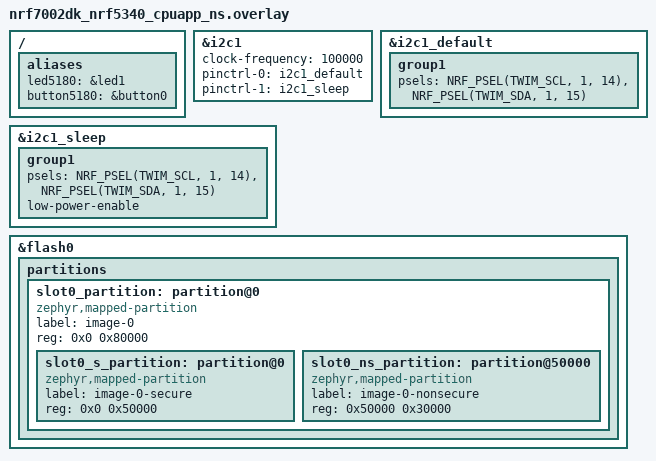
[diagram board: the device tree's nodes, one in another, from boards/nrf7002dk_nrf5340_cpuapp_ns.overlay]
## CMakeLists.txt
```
cmake_minimum_required(VERSION 3.20.0)

find_package(Zephyr REQUIRED HINTS $ENV{ZEPHYR_BASE})
project(blinky)

target_sources(app PRIVATE src/main.c)
target_sources_ifdef(CONFIG_LAB_BME280 app PRIVATE bme280/bme280_raw.c bme280/bme280_app.c)

if(CONFIG_SUM_PRINT)
	target_sources(app PRIVATE sum_printk/sum_printk.c)
	target_include_directories(app PRIVATE sum_printk)
elseif(CONFIG_SUM_LOG)
	target_sources(app PRIVATE sum_log/sum_log.c)
	target_include_directories(app PRIVATE sum_log)
endif()
```

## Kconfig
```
mainmenu "Sum Application Configuration"

choice SUM_IMPLEMENTATION
	prompt "Select the sum output implementation"
	default SUM_PRINT

config SUM_PRINT
	bool "Use printk implementation"
	select PRINTK

config SUM_LOG
	bool "Use Logger implementation"
	select LOG

endchoice

config LAB_BME280
	bool "Part 8 BME280 register temperature reader"
	depends on I2C

source "Kconfig.zephyr"
```

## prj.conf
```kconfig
CONFIG_GPIO=y
CONFIG_CONSOLE=y
CONFIG_SERIAL=y
CONFIG_UART_CONSOLE=y

CONFIG_LOG=y
CONFIG_LOG_DEFAULT_LEVEL=3
CONFIG_SUM_LOG=y

CONFIG_I2C=y
CONFIG_SENSOR=y
CONFIG_LAB_BME280=y
# UART1 and I2C1 share a hardware instance; reserve it for I2C1.
CONFIG_TFM_SECURE_UART=n
CONFIG_TFM_LOG_LEVEL_SILENCE=y
```

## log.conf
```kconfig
# Apply after prj.conf with -DEXTRA_CONF_FILE=log.conf.
CONFIG_SUM_PRINT=n
CONFIG_SUM_LOG=y
CONFIG_LOG=y
CONFIG_LOG_DEFAULT_LEVEL=3
CONFIG_LOG_MODE_DEFERRED=y
CONFIG_LOG_BACKEND_UART=y
```

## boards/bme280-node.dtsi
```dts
bme280_lab: bme280@77 {
 compatible = "i2c-device";
 reg = <0x77>;
 status = "okay";
};
```

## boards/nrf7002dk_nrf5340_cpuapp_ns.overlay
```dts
/ {
	aliases {
		led5180 = &led1;
		button5180 = &button0;
	};
};

&i2c1 {
	status = "okay";
	clock-frequency = <100000>;
	pinctrl-0 = <&i2c1_default>;
	pinctrl-1 = <&i2c1_sleep>;
	pinctrl-names = "default", "sleep";
	#include "bme280-node.dtsi"
};

&i2c1_default {
	group1 {
		psels = <NRF_PSEL(TWIM_SCL, 1, 14)>, <NRF_PSEL(TWIM_SDA, 1, 15)>;
	};
};

&i2c1_sleep {
	group1 {
		psels = <NRF_PSEL(TWIM_SCL, 1, 14)>, <NRF_PSEL(TWIM_SDA, 1, 15)>;
		low-power-enable;
	};
};

/* This application boots TF-M directly, without MCUboot. */
/delete-node/ &boot_partition;
/delete-node/ &slot0_partition;

&flash0 {
	partitions {
		slot0_partition: partition@0 {
			compatible = "zephyr,mapped-partition";
			label = "image-0";
			reg = <0x0 0x80000>;
			ranges = <0x0 0x0 0x80000>;
			#address-cells = <1>;
			#size-cells = <1>;

			slot0_s_partition: partition@0 {
				compatible = "zephyr,mapped-partition";
				label = "image-0-secure";
				reg = <0x0 0x50000>;
			};

			slot0_ns_partition: partition@50000 {
				compatible = "zephyr,mapped-partition";
				label = "image-0-nonsecure";
				reg = <0x50000 0x30000>;
			};
		};
	};
};
```

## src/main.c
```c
/*
 * Copyright (c) 2016 Intel Corporation
 *
 * SPDX-License-Identifier: Apache-2.0
 */

#include <stdio.h>
#include <zephyr/kernel.h>
#include <zephyr/drivers/gpio.h>

#ifdef CONFIG_SUM_PRINT
#include "sum_printk.h"
#elif defined(CONFIG_SUM_LOG)
#include "sum_log.h"
#endif

/* 1000 msec = 1 sec */
#define SLEEP_TIME_MS   2000
#define BUTTON_POLL_TIME_MS 20

/* The devicetree node identifier for the "led0" alias. */
//#define LED0_NODE DT_ALIAS(led0)
//#define BUTTON_NODE DT_ALIAS(sw0)
#define LED5180_NODE DT_ALIAS(led5180)
#define BUTTON5180_NODE DT_ALIAS(button5180)

/*
 * A build error on this line means your board is unsupported.
 * See the sample documentation for information on how to fix this.
*/
//static const struct gpio_dt_spec button = GPIO_DT_SPEC_GET(BUTTON_NODE, gpios);

static const struct gpio_dt_spec led = GPIO_DT_SPEC_GET(LED5180_NODE, gpios);

static const struct gpio_dt_spec button = GPIO_DT_SPEC_GET(BUTTON5180_NODE, gpios);

int main(void)
{
	int ret;
	int button_state;
	int sum_result;
	bool led_state = true;
	bool last_button_state = false;

	/* Light LED2 before sleeping or printing to diagnose startup. */
	if (!gpio_is_ready_dt(&led)) {
		printf("LED device is not ready\n");
		return 0;
	}

	ret = gpio_pin_configure_dt(&led, GPIO_OUTPUT_ACTIVE);
	if (ret < 0) {
		printf("Failed to configure LED\n");
		return 0;
	}

	/* Wait five seconds for the serial monitor to reconnect. */
	k_msleep(5000);

	/* Part 6: run the selected sum implementation once. */
#ifdef CONFIG_SUM_PRINT
	sum_result = sum_printk(3, 5);
#elif defined(CONFIG_SUM_LOG)
	sum_result = sum_log(3, 5);
#endif
	(void)sum_result;

	/* Part 5: button setup. */
	if (!gpio_is_ready_dt(&button)) {
		printf("Button device is not ready\n");
		return 0;
	}

	ret = gpio_pin_configure_dt(&button, GPIO_INPUT);
	if (ret < 0) {
		printf("Failed to configure button\n");
		return 0;
	}

	while (1) {
		button_state = gpio_pin_get_dt(&button);

		if (button_state < 0) {
			printf("Failed to read button\n");
			return 0;
		}

		if (button_state && !last_button_state) {
			ret = gpio_pin_toggle_dt(&led);

			if (ret < 0) {
				printf("Failed to toggle LED\n");
				return 0;
			}

			led_state = !led_state;
			printf("LED state: %s\n",
			       led_state ? "ON" : "OFF");
		}

		last_button_state = button_state;
		k_msleep(BUTTON_POLL_TIME_MS);
	}

	return 0;
}
```
